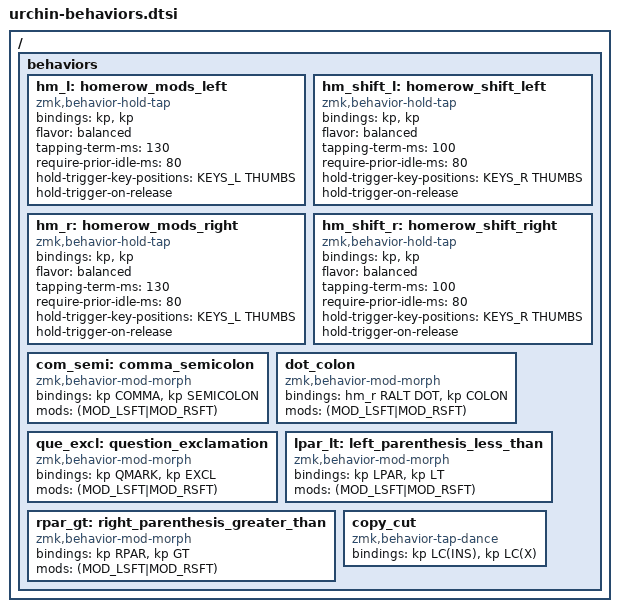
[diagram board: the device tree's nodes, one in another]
/* ┌────┬────┬────┬────┬────┐┌────┬────┬────┬────┬────┐
 * │  0 │  1 │  2 │  3 │  4 ││  5 │  6 │  7 │  8 │  9 │
 * ├────┼────┼────┼────┼────┤├────┼────┼────┼────┼────┤
 * │ 10 │ 11 │ 12 │ 13 │ 14 ││ 15 │ 16 │ 17 │ 18 │ 19 │
 * ├────┼────┼────┼────┼────┤├────┼────┼────┼────┼────┤
 * │ 20 │ 21 │ 22 │ 23 │ 24 ││ 25 │ 26 │ 27 │ 28 │ 29 │
 * └────┴────┴────┼────┼────┤├────┼────┼────┴────┴────┘
 *                │ 30 │ 31 ││ 32 │ 33 │
 *                └────┴────┘└────┴────┘
 */

#define KEYS_L 5 6 7 8 9 15 16 17 18 19 25 26 27 28 29
#define KEYS_R 0 1 2 3 4 10 11 12 13 14 20 21 22 23 24
#define THUMBS 30 31 32 33

/ {
  behaviors {
    hm_l: homerow_mods_left {
      compatible = "zmk,behavior-hold-tap";
      #binding-cells = <2>;
      bindings = <&kp>, <&kp>;
      flavor = "balanced";
      tapping-term-ms = <130>;
      require-prior-idle-ms = <80>;
      hold-trigger-key-positions = <KEYS_L THUMBS>;
      hold-trigger-on-release;
    };

    hm_shift_l: homerow_shift_left {
      compatible = "zmk,behavior-hold-tap";
      #binding-cells = <2>;
      bindings = <&kp>, <&kp>;
      flavor = "balanced";
      tapping-term-ms = <100>;
      require-prior-idle-ms = <80>;
      hold-trigger-key-positions = <KEYS_R THUMBS>;
      hold-trigger-on-release;
    };

    hm_r: homerow_mods_right {
      compatible = "zmk,behavior-hold-tap";
      #binding-cells = <2>;
      bindings = <&kp>, <&kp>;
      flavor = "balanced";
      tapping-term-ms = <130>;
      require-prior-idle-ms = <80>;
      hold-trigger-key-positions = <KEYS_L THUMBS>;
      hold-trigger-on-release;
    };
  
    hm_shift_r: homerow_shift_right {
      compatible = "zmk,behavior-hold-tap";
      #binding-cells = <2>;
      bindings = <&kp>, <&kp>;
      flavor = "balanced";
      tapping-term-ms = <100>;
      require-prior-idle-ms = <80>;
      hold-trigger-key-positions = <KEYS_R THUMBS>;
      hold-trigger-on-release;
    };

    com_semi: comma_semicolon {
      compatible = "zmk,behavior-mod-morph";
      #binding-cells = <0>;
      bindings = <&kp COMMA>, <&kp SEMICOLON>;
      mods = <(MOD_LSFT|MOD_RSFT)>;
    };

    dot_colon: dot_colon {
      compatible = "zmk,behavior-mod-morph";
      #binding-cells = <0>;
      bindings = <&hm_r RALT DOT>, <&kp COLON>;
      mods = <(MOD_LSFT|MOD_RSFT)>;
    };

    que_excl: question_exclamation {
      compatible = "zmk,behavior-mod-morph";
      #binding-cells = <0>;
      bindings = <&kp QMARK>, <&kp EXCL>;
      mods = <(MOD_LSFT|MOD_RSFT)>;
    };

    lpar_lt: left_parenthesis_less_than {
      compatible = "zmk,behavior-mod-morph";
      #binding-cells = <0>;
      bindings = <&kp LPAR>, <&kp LT>;
      mods = <(MOD_LSFT|MOD_RSFT)>;
    };

    rpar_gt: right_parenthesis_greater_than {
      compatible = "zmk,behavior-mod-morph";
      #binding-cells = <0>;
      bindings = <&kp RPAR>, <&kp GT>;
      mods = <(MOD_LSFT|MOD_RSFT)>;
    };

    copy_cut: copy_cut {
      compatible = "zmk,behavior-tap-dance";
      #binding-cells = <0>;
      bindings = <&kp LC(INS)>, <&kp LC(X)>;
    };
  };
};
